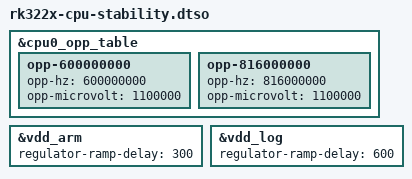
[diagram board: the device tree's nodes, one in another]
/dts-v1/;
/plugin/;

/ {

	/*
		Device tree overlay that tries to overcome issues on power regulators (expecially ARM
		power regulator) increasing lowest voltage and adding settling time to allow voltage
		stabilization
	*/
};

&cpu0_opp_table {
	/*
		Increase 600 and 800 Mhz operating points voltage to decrease the range
		between minimum and maximum voltages
	*/
	opp-600000000 {
		opp-hz = /bits/ 64 <600000000>;
		opp-microvolt = <1100000>;
	};

	opp-816000000 {
		opp-hz = /bits/ 64 <816000000>;
		opp-microvolt = <1100000>;
	};
};

&vdd_arm {
	regulator-ramp-delay = <300>; // 30 uV/us, so 0.3v transition settling time is 1ms
};

&vdd_log {
	regulator-ramp-delay = <600>; // 600 uV/us, so 0,3v transition settling time is 0.5ms
};
